# BL808 register map
Vendor: Bouffalo Lab; File version: 0.1
Registers are 32-bit, read-write, reset 0x0 unless marked. A register's access mark holds for its fields unless they carry their own. Offsets are from the block's base; [hi:lo] are bit positions; {n}, {i} and the like mark numbered series; 'fields as' and 'values as' point back to an identical list.

## GLB — Global configuration register
Base 0x20000000
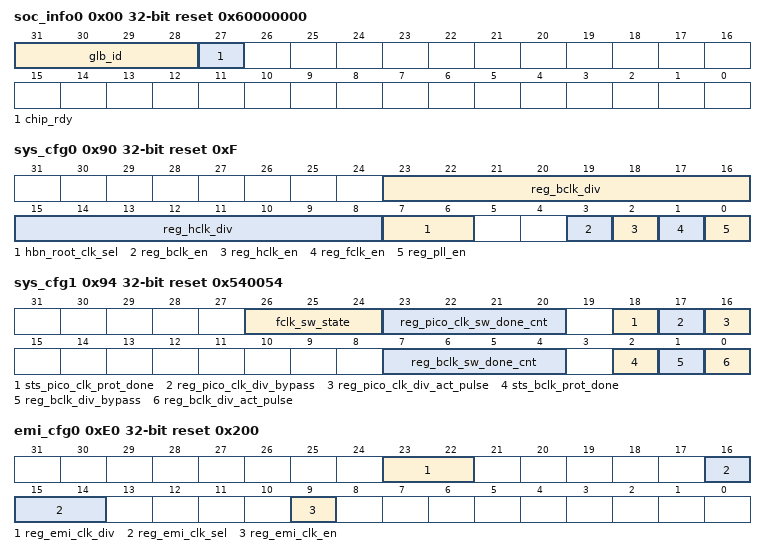
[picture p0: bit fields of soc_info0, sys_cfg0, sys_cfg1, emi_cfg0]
0x00 soc_info0 reset 0x60000000
  [31:28] glb_id ro, [27] chip_rdy ro
0x50 core_cfg16
  [31:0] np_int_sta0 ro
0x54 core_cfg17
  [31:0] np_int_sta1 ro
0x58 core_cfg18
  [31:0] np_int_mask0
0x5C core_cfg19
  [31:0] np_int_mask1
0x60 core_cfg20
  [31:0] np_int_clr0 wo
0x64 core_cfg21
  [31:0] np_int_clr1 wo
0x68 core_cfg22 reset 0xFFFFFFFF
  [31:0] reg_e902_int_en0
0x6C core_cfg23 reset 0xFFFFFFFF
  [31:0] reg_e902_int_en1
0x70 core_cfg24
  [31:0] sts_e902_int_bus_0 ro
0x74 core_cfg25
  [31:0] sts_e902_int_bus_1 ro
0x90 sys_cfg0 reset 0xF
  [23:16] reg_bclk_div, [15:8] reg_hclk_div, [7:6] hbn_root_clk_sel ro, [3] reg_bclk_en, [2] reg_hclk_en, [1] reg_fclk_en, [0] reg_pll_en
0x94 sys_cfg1 reset 0x540054
  [26:24] fclk_sw_state ro, [23:20] reg_pico_clk_sw_done_cnt, [18] sts_pico_clk_prot_done ro, [17] reg_pico_clk_div_bypass, [16] reg_pico_clk_div_act_pulse wo, [7:4] reg_bclk_sw_done_cnt, [2] sts_bclk_prot_done ro, [1] reg_bclk_div_bypass, [0] reg_bclk_div_act_pulse wo
0xA0 bus_cfg0 reset 0xFFFF
  [15:0] rg_apb2_pck_force
0xE0 emi_cfg0 reset 0x200
  [23:22] reg_emi_clk_div, [16:14] reg_emi_clk_sel, [9] reg_emi_clk_en
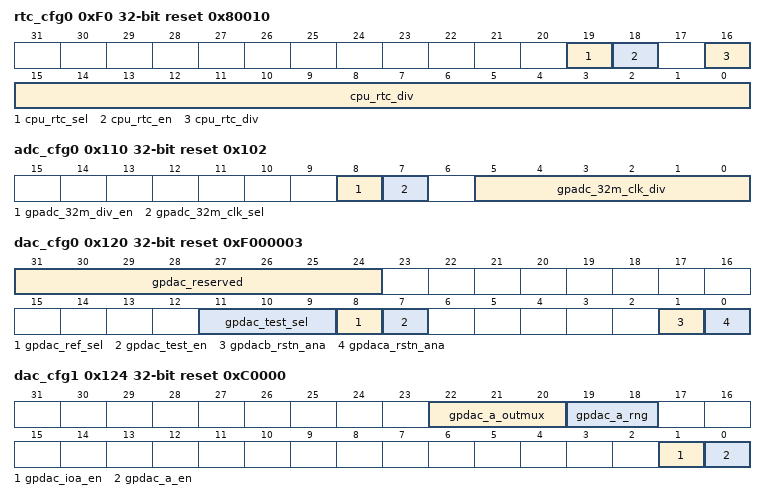
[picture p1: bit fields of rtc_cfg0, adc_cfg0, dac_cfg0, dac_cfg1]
0xF0 rtc_cfg0 reset 0x80010
  [19] cpu_rtc_sel, [18] cpu_rtc_en, [16:0] cpu_rtc_div
0x110 adc_cfg0 reset 0x102
  [8] gpadc_32m_div_en, [7] gpadc_32m_clk_sel, [5:0] gpadc_32m_clk_div
0x120 dac_cfg0 reset 0xF000003
  [31:24] gpdac_reserved, [11:9] gpdac_test_sel, [8] gpdac_ref_sel, [7] gpdac_test_en, [1] gpdacb_rstn_ana, [0] gpdaca_rstn_ana
0x124 dac_cfg1 reset 0xC0000
  [22:20] gpdac_a_outmux, [19:18] gpdac_a_rng, [1] gpdac_ioa_en, [0] gpdac_a_en
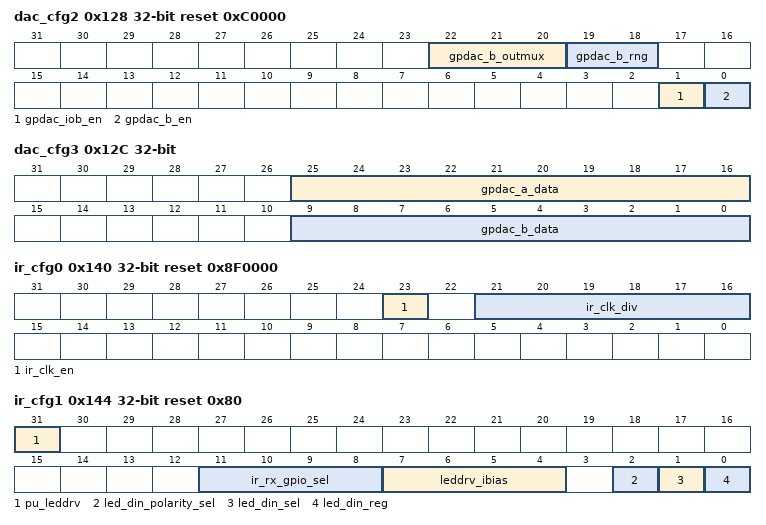
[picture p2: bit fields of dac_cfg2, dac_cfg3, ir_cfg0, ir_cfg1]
0x128 dac_cfg2 reset 0xC0000
  [22:20] gpdac_b_outmux, [19:18] gpdac_b_rng, [1] gpdac_iob_en, [0] gpdac_b_en
0x12C dac_cfg3
  [25:16] gpdac_a_data, [9:0] gpdac_b_data
0x130 dma_cfg0 reset 0xFF000000
  [31:24] dma_clk_en
0x134 dma_cfg1 reset 0xFF000000
  [31:24] dma2_clk_en
0x138 dma_cfg2
  [31:0] reg_dma_cn_sel
0x140 ir_cfg0 reset 0x8F0000
  [23] ir_clk_en, [21:16] ir_clk_div
0x144 ir_cfg1 reset 0x80
  [31] pu_leddrv, [11:8] ir_rx_gpio_sel, [7:4] leddrv_ibias, [2] led_din_polarity_sel, [1] led_din_sel, [0] led_din_reg
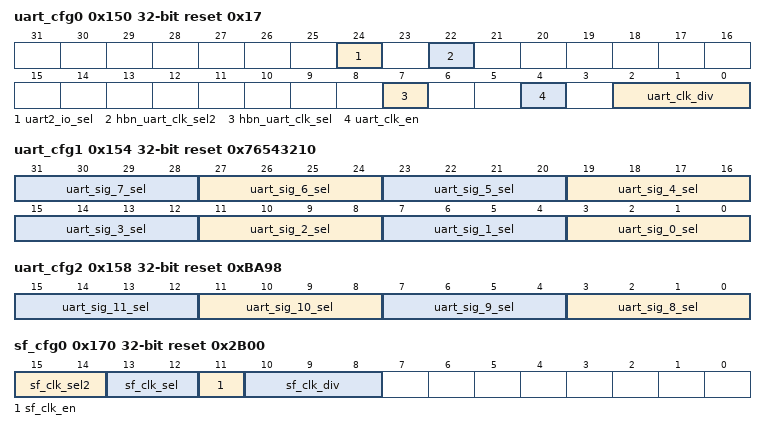
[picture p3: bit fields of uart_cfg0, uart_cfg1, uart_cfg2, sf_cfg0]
0x150 uart_cfg0 reset 0x17
  [24] uart2_io_sel, [22] hbn_uart_clk_sel2 ro, [7] hbn_uart_clk_sel ro, [4] uart_clk_en, [2:0] uart_clk_div
0x154 uart_cfg1 reset 0x76543210
  [4n+3:4n] uart_sig_{n}_sel (n=0..7)
0x158 uart_cfg2 reset 0xBA98
  [4n-29:4n-32] uart_sig_{n}_sel (n=8..11)
0x170 sf_cfg0 reset 0x2B00
  [15:14] sf_clk_sel2, [13:12] sf_clk_sel, [11] sf_clk_en, [10:8] sf_clk_div
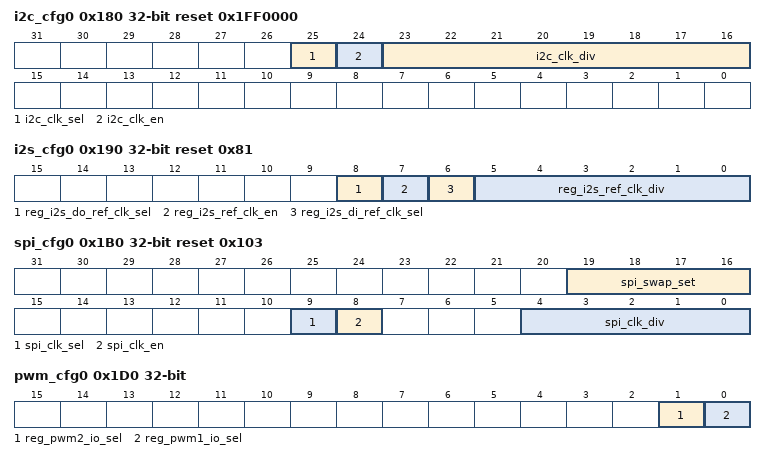
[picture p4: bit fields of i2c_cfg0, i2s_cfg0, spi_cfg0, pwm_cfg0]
0x180 i2c_cfg0 reset 0x1FF0000
  [25] i2c_clk_sel, [24] i2c_clk_en, [23:16] i2c_clk_div
0x190 i2s_cfg0 reset 0x81
  [8] reg_i2s_do_ref_clk_sel, [7] reg_i2s_ref_clk_en, [6] reg_i2s_di_ref_clk_sel, [5:0] reg_i2s_ref_clk_div
0x1B0 spi_cfg0 reset 0x103
  [19:16] spi_swap_set, [9] spi_clk_sel, [8] spi_clk_en, [4:0] spi_clk_div
0x1C0 qdec_cfg0
0x1D0 pwm_cfg0
  [1] reg_pwm2_io_sel, [0] reg_pwm1_io_sel
0x1E0 pdm_cfg0
  [0] reg_pdm_io_sel
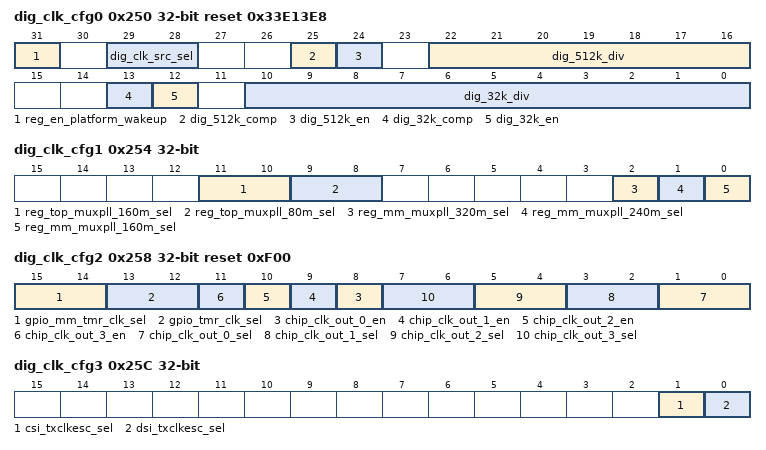
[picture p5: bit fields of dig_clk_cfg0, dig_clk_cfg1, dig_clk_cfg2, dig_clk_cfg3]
0x250 dig_clk_cfg0 reset 0x33E13E8
  [31] reg_en_platform_wakeup, [29:28] dig_clk_src_sel, [25] dig_512k_comp, [24] dig_512k_en, [22:16] dig_512k_div, [13] dig_32k_comp, [12] dig_32k_en, [10:0] dig_32k_div
0x254 dig_clk_cfg1
  [11:10] reg_top_muxpll_160m_sel, [9:8] reg_top_muxpll_80m_sel, [2] reg_mm_muxpll_320m_sel, [1] reg_mm_muxpll_240m_sel, [0] reg_mm_muxpll_160m_sel
0x258 dig_clk_cfg2 reset 0xF00
  [15:14] gpio_mm_tmr_clk_sel, [13:12] gpio_tmr_clk_sel, [n+8] chip_clk_out_{n}_en (n=0..3), [2n+1:2n] chip_clk_out_{n}_sel (n=0..3)
0x25C dig_clk_cfg3
  [1] csi_txclkesc_sel, [0] dsi_txclkesc_sel
0x260 rf_cfg0 reset 0x200
  [9] cfg_inv_rf2_test_clk_o
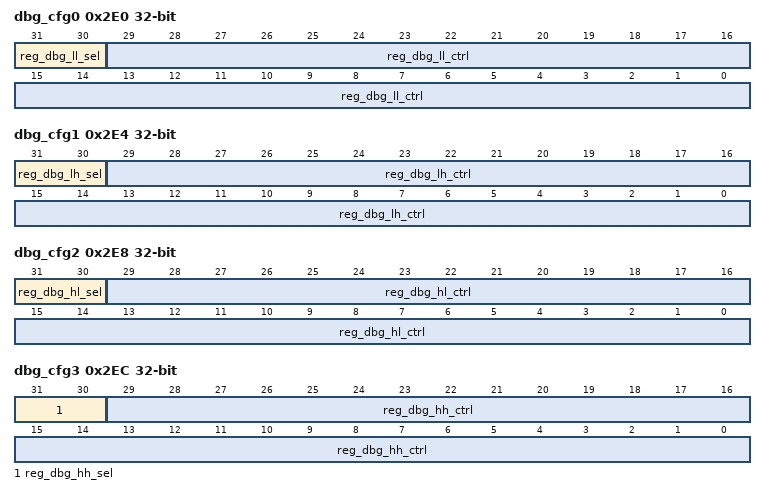
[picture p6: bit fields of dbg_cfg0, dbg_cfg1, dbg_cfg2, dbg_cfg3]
0x2E0 dbg_cfg0
  [31:30] reg_dbg_ll_sel, [29:0] reg_dbg_ll_ctrl
0x2E4 dbg_cfg1
  [31:30] reg_dbg_lh_sel, [29:0] reg_dbg_lh_ctrl
0x2E8 dbg_cfg2
  [31:30] reg_dbg_hl_sel, [29:0] reg_dbg_hl_ctrl
0x2EC dbg_cfg3
  [31:30] reg_dbg_hh_sel, [29:0] reg_dbg_hh_ctrl
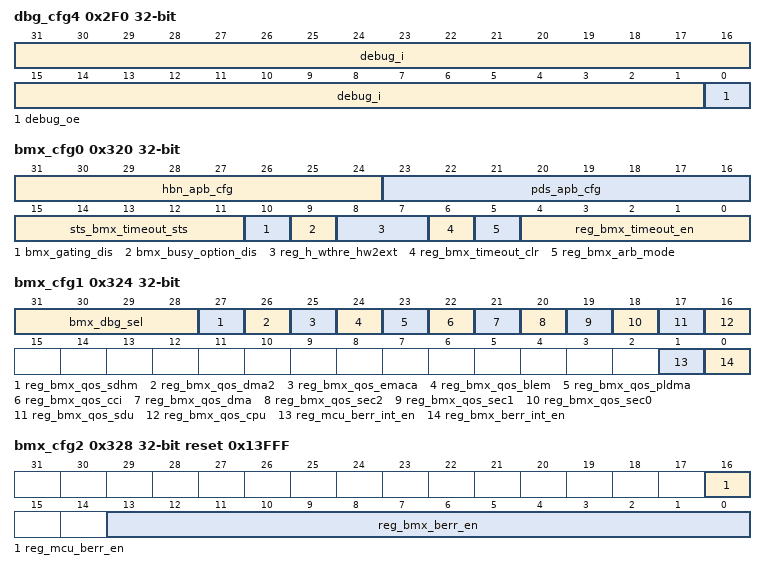
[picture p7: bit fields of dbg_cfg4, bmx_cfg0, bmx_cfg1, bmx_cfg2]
0x2F0 dbg_cfg4
  [31:1] debug_i ro, [0] debug_oe
0x300 mbist_cfg0
  [0] mbist_mode
0x320 bmx_cfg0
  [31:24] hbn_apb_cfg, [23:16] pds_apb_cfg, [15:11] sts_bmx_timeout_sts ro, [10] bmx_gating_dis, [9] bmx_busy_option_dis, [8:7] reg_h_wthre_hw2ext, [6] reg_bmx_timeout_clr, [5] reg_bmx_arb_mode, [4:0] reg_bmx_timeout_en
0x324 bmx_cfg1
  [31:28] bmx_dbg_sel, [27] reg_bmx_qos_sdhm, [26] reg_bmx_qos_dma2, [25] reg_bmx_qos_emaca, [24] reg_bmx_qos_blem, [23] reg_bmx_qos_pldma, [22] reg_bmx_qos_cci, [21] reg_bmx_qos_dma, [20] reg_bmx_qos_sec2, [19] reg_bmx_qos_sec1, [18] reg_bmx_qos_sec0, [17] reg_bmx_qos_sdu, [16] reg_bmx_qos_cpu, [1] reg_mcu_berr_int_en, [0] reg_bmx_berr_int_en
0x328 bmx_cfg2 reset 0x13FFF
  [16] reg_mcu_berr_en, [13:0] reg_bmx_berr_en
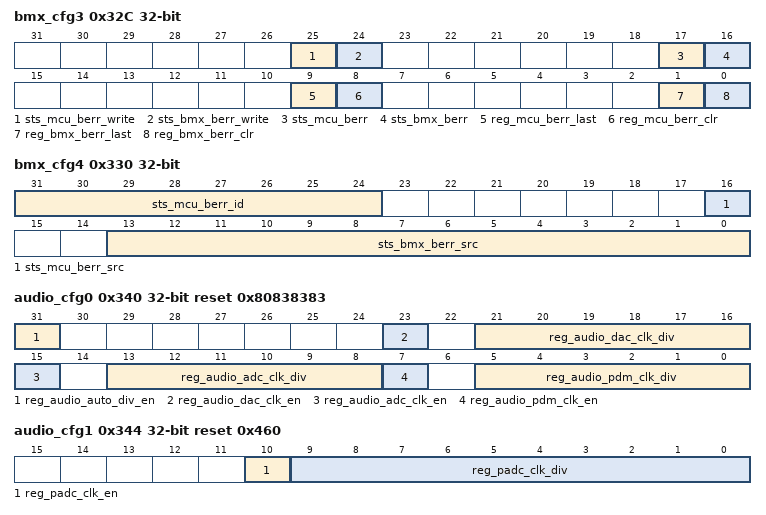
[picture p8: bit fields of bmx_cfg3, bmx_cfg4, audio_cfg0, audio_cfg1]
0x32C bmx_cfg3
  [25] sts_mcu_berr_write ro, [24] sts_bmx_berr_write ro, [17] sts_mcu_berr ro, [16] sts_bmx_berr ro, [9] reg_mcu_berr_last, [8] reg_mcu_berr_clr, [1] reg_bmx_berr_last, [0] reg_bmx_berr_clr
0x330 bmx_cfg4
  [31:24] sts_mcu_berr_id ro, [16] sts_mcu_berr_src ro, [13:0] sts_bmx_berr_src ro
0x334 bmx_cfg5
  [31:0] sts_bmx_berr_addr ro
0x338 bmx_cfg6
  [31:0] sts_mcu_berr_addr ro
0x340 audio_cfg0 reset 0x80838383
  [31] reg_audio_auto_div_en, [23] reg_audio_dac_clk_en, [21:16] reg_audio_dac_clk_div, [15] reg_audio_adc_clk_en, [13:8] reg_audio_adc_clk_div, [7] reg_audio_pdm_clk_en, [5:0] reg_audio_pdm_clk_div
0x344 audio_cfg1 reset 0x460
  [10] reg_padc_clk_en, [9:0] reg_padc_clk_div
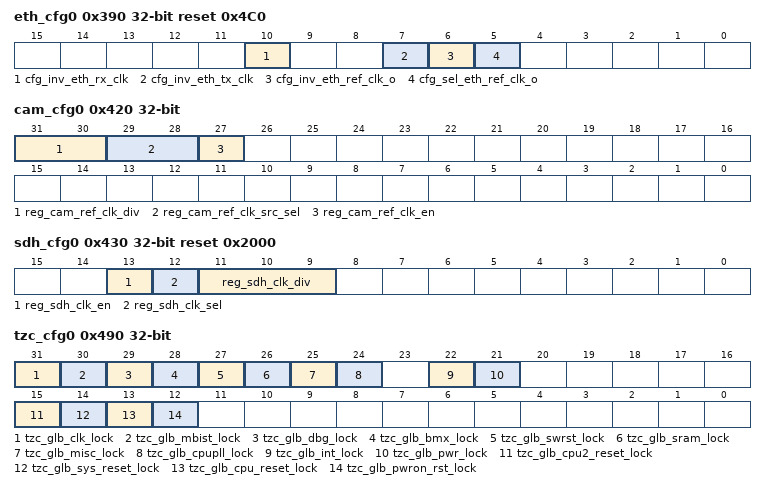
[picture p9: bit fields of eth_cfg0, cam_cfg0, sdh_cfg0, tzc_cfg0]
0x390 eth_cfg0 reset 0x4C0
  [10] cfg_inv_eth_rx_clk, [7] cfg_inv_eth_tx_clk, [6] cfg_inv_eth_ref_clk_o, [5] cfg_sel_eth_ref_clk_o
0x420 cam_cfg0
  [31:30] reg_cam_ref_clk_div, [29:28] reg_cam_ref_clk_src_sel, [27] reg_cam_ref_clk_en
0x430 sdh_cfg0 reset 0x2000
  [13] reg_sdh_clk_en, [12] reg_sdh_clk_sel, [11:9] reg_sdh_clk_div
0x490 tzc_cfg0
  [31] tzc_glb_clk_lock ro, [30] tzc_glb_mbist_lock ro, [29] tzc_glb_dbg_lock ro, [28] tzc_glb_bmx_lock ro, [27] tzc_glb_swrst_lock ro, [26] tzc_glb_sram_lock ro, [25] tzc_glb_misc_lock ro, [24] tzc_glb_cpupll_lock ro, [22] tzc_glb_int_lock ro, [21] tzc_glb_pwr_lock ro, [15] tzc_glb_cpu2_reset_lock ro, [14] tzc_glb_sys_reset_lock ro, [13] tzc_glb_cpu_reset_lock ro, [12] tzc_glb_pwron_rst_lock ro
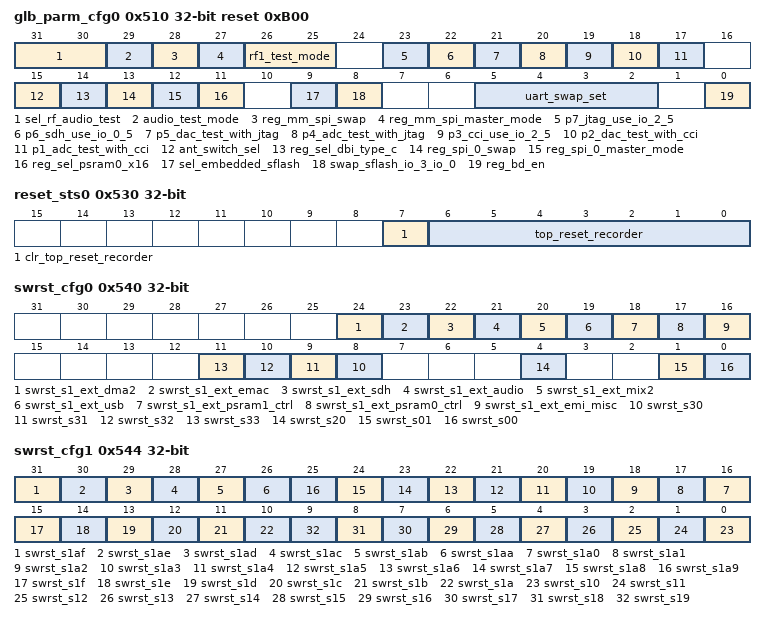
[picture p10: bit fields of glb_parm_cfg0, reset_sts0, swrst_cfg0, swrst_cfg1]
0x510 glb_parm_cfg0 reset 0xB00
  [31:30] sel_rf_audio_test, [29] audio_test_mode, [28] reg_mm_spi_swap, [27] reg_mm_spi_master_mode, [26:25] rf1_test_mode, [23] p7_jtag_use_io_2_5, [22] p6_sdh_use_io_0_5, [21] p5_dac_test_with_jtag, [20] p4_adc_test_with_jtag, [19] p3_cci_use_io_2_5, [18] p2_dac_test_with_cci, [17] p1_adc_test_with_cci, [15] ant_switch_sel, [14] reg_sel_dbi_type_c, [13] reg_spi_0_swap, [12] reg_spi_0_master_mode, [11] reg_sel_psram0_x16, [9] sel_embedded_sflash, [8] swap_sflash_io_3_io_0, [5:2] uart_swap_set, [0] reg_bd_en
0x520 debug_cfg0
0x524 debug_cfg1
  [20] debug_ndreset_gate
0x530 reset_sts0
  [7] clr_top_reset_recorder, [6:0] top_reset_recorder ro
0x540 swrst_cfg0 — swrst_s1_ext + swrst_s3 + swrst_s2
  [24] swrst_s1_ext_dma2, [23] swrst_s1_ext_emac, [22] swrst_s1_ext_sdh, [21] swrst_s1_ext_audio, [20] swrst_s1_ext_mix2, [19] swrst_s1_ext_usb, [18] swrst_s1_ext_psram1_ctrl, [17] swrst_s1_ext_psram0_ctrl, [16] swrst_s1_ext_emi_misc, [n-22] swrst_s{n} (n=30..33), [4] swrst_s20, [1] swrst_s01, [0] swrst_s00
0x544 swrst_cfg1 — swrst_s1
  [31] swrst_s1af, [30] swrst_s1ae, [29] swrst_s1ad, [28] swrst_s1ac, [27] swrst_s1ab, [26] swrst_s1aa, [n+16] swrst_s1a{n} (n=0..9), [15] swrst_s1f, [14] swrst_s1e, [13] swrst_s1d, [12] swrst_s1c, [11] swrst_s1b, [10] swrst_s1a, [n-10] swrst_s{n} (n=10..19)
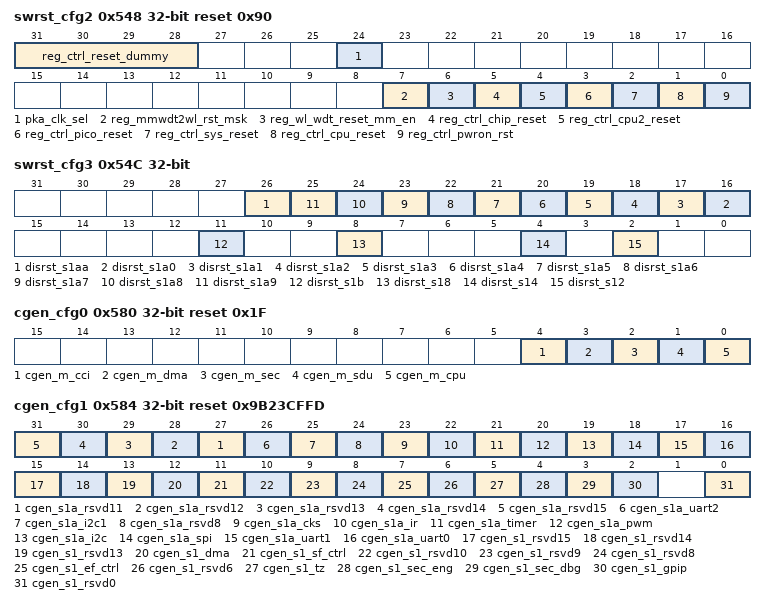
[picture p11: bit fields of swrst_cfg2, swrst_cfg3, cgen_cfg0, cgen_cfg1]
0x548 swrst_cfg2 reset 0x90
  [31:28] reg_ctrl_reset_dummy, [24] pka_clk_sel, [7] reg_mmwdt2wl_rst_msk, [6] reg_wl_wdt_reset_mm_en, [5] reg_ctrl_chip_reset, [4] reg_ctrl_cpu2_reset, [3] reg_ctrl_pico_reset, [2] reg_ctrl_sys_reset, [1] reg_ctrl_cpu_reset, [0] reg_ctrl_pwron_rst
0x54C swrst_cfg3 — Disable hreset
  [26] disrst_s1aa, [n+16] disrst_s1a{n} (n=0..9), [11] disrst_s1b, [8] disrst_s18, [4] disrst_s14, [2] disrst_s12
0x580 cgen_cfg0 reset 0x1F — cgen_m
  [4] cgen_m_cci, [3] cgen_m_dma, [2] cgen_m_sec, [1] cgen_m_sdu, [0] cgen_m_cpu
0x584 cgen_cfg1 reset 0x9B23CFFD — cgen_s1a + cgen_s1
  [n+16] cgen_s1a_rsvd{n} (n=11..15), [26] cgen_s1a_uart2, [25] cgen_s1a_i2c1, [24] cgen_s1a_rsvd8, [23] cgen_s1a_cks, [22] cgen_s1a_ir, [21] cgen_s1a_timer, [20] cgen_s1a_pwm, [19] cgen_s1a_i2c, [18] cgen_s1a_spi, [17] cgen_s1a_uart1, [16] cgen_s1a_uart0, [15] cgen_s1_rsvd15, [14] cgen_s1_rsvd14, [13] cgen_s1_rsvd13, [12] cgen_s1_dma, [11] cgen_s1_sf_ctrl, [10] cgen_s1_rsvd10, [9] cgen_s1_rsvd9, [8] cgen_s1_rsvd8, [7] cgen_s1_ef_ctrl, [6] cgen_s1_rsvd6, [5] cgen_s1_tz, [4] cgen_s1_sec_eng, [3] cgen_s1_sec_dbg, [2] cgen_s1_gpip, [0] cgen_s1_rsvd0
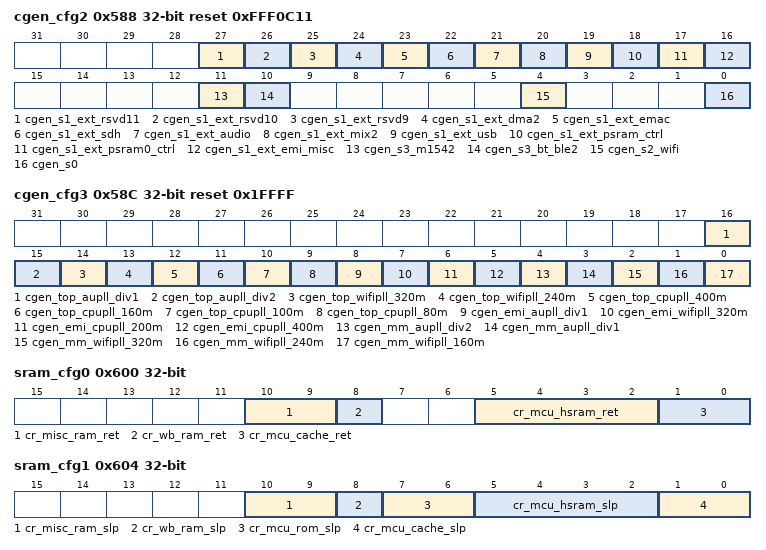
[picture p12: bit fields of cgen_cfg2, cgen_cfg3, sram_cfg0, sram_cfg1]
0x588 cgen_cfg2 reset 0xFFF0C11 — cgen_s1_ext + cgen_s3
  [27] cgen_s1_ext_rsvd11, [26] cgen_s1_ext_rsvd10, [25] cgen_s1_ext_rsvd9, [24] cgen_s1_ext_dma2, [23] cgen_s1_ext_emac, [22] cgen_s1_ext_sdh, [21] cgen_s1_ext_audio, [20] cgen_s1_ext_mix2, [19] cgen_s1_ext_usb, [18] cgen_s1_ext_psram_ctrl, [17] cgen_s1_ext_psram0_ctrl, [16] cgen_s1_ext_emi_misc, [11] cgen_s3_m1542, [10] cgen_s3_bt_ble2, [4] cgen_s2_wifi, [0] cgen_s0
0x58C cgen_cfg3 reset 0x1FFFF
  [16] cgen_top_aupll_div1, [15] cgen_top_aupll_div2, [14] cgen_top_wifipll_320m, [13] cgen_top_wifipll_240m, [12] cgen_top_cpupll_400m, [11] cgen_top_cpupll_160m, [10] cgen_top_cpupll_100m, [9] cgen_top_cpupll_80m, [8] cgen_emi_aupll_div1, [7] cgen_emi_wifipll_320m, [6] cgen_emi_cpupll_200m, [5] cgen_emi_cpupll_400m, [4] cgen_mm_aupll_div2, [3] cgen_mm_aupll_div1, [2] cgen_mm_wifipll_320m, [1] cgen_mm_wifipll_240m, [0] cgen_mm_wifipll_160m
{0x5C0+4i} hw_rsv{i} (i=0..2)
0x5CC hw_rsv3 reset 0xFFFFFFFF
0x600 sram_cfg0 — reg_sram_ret
  [10:9] cr_misc_ram_ret, [8] cr_wb_ram_ret, [5:2] cr_mcu_hsram_ret, [1:0] cr_mcu_cache_ret
0x604 sram_cfg1 — reg_sram_slp
  [10:9] cr_misc_ram_slp, [8] cr_wb_ram_slp, [7:6] cr_mcu_rom_slp, [5:2] cr_mcu_hsram_slp, [1:0] cr_mcu_cache_slp
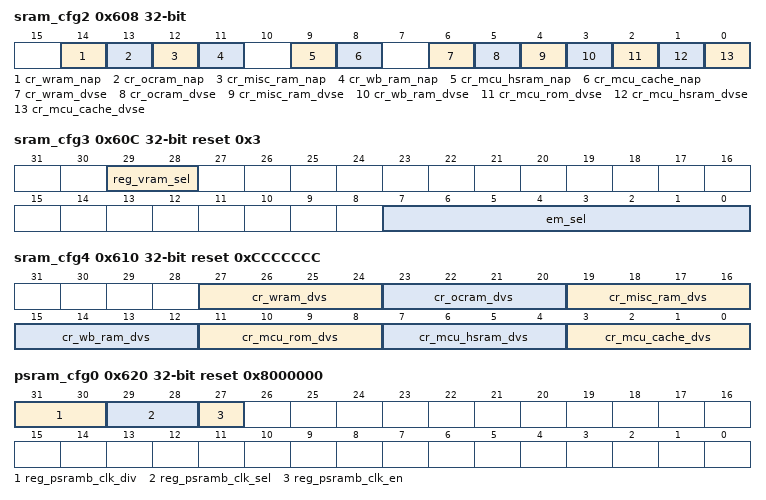
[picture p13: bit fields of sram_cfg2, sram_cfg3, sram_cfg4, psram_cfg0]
0x608 sram_cfg2 — reg_sram_parm
  [14] cr_wram_nap, [13] cr_ocram_nap, [12] cr_misc_ram_nap, [11] cr_wb_ram_nap, [9] cr_mcu_hsram_nap, [8] cr_mcu_cache_nap, [6] cr_wram_dvse, [5] cr_ocram_dvse, [4] cr_misc_ram_dvse, [3] cr_wb_ram_dvse, [2] cr_mcu_rom_dvse, [1] cr_mcu_hsram_dvse, [0] cr_mcu_cache_dvse
0x60C sram_cfg3 reset 0x3
  [29:28] reg_vram_sel, [7:0] em_sel
0x610 sram_cfg4 reset 0xCCCCCCC — reg_sram_parm2
  [27:24] cr_wram_dvs, [23:20] cr_ocram_dvs, [19:16] cr_misc_ram_dvs, [15:12] cr_wb_ram_dvs, [11:8] cr_mcu_rom_dvs, [7:4] cr_mcu_hsram_dvs, [3:0] cr_mcu_cache_dvs
0x620 psram_cfg0 reset 0x8000000
  [31:30] reg_psramb_clk_div, [29:28] reg_psramb_clk_sel, [27] reg_psramb_clk_en
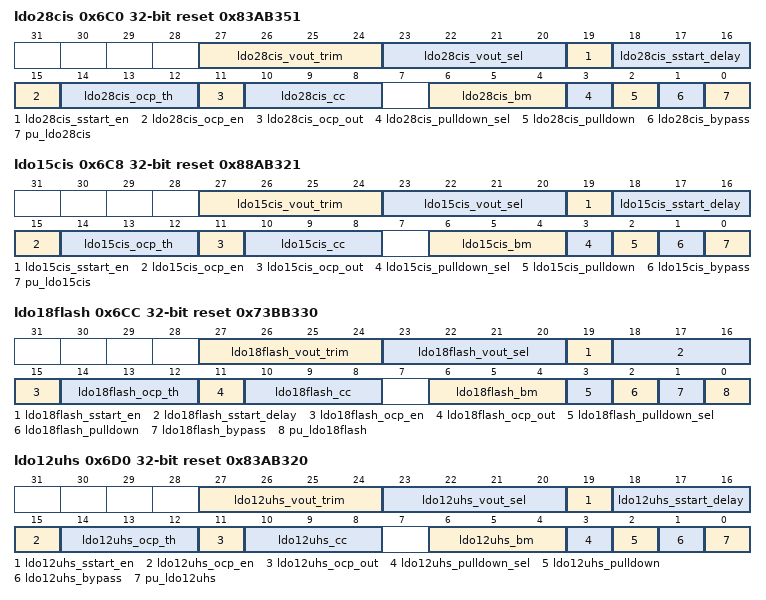
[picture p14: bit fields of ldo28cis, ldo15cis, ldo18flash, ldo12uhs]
0x6C0 ldo28cis reset 0x83AB351
  [27:24] ldo28cis_vout_trim, [23:20] ldo28cis_vout_sel, [19] ldo28cis_sstart_en, [18:16] ldo28cis_sstart_delay, [15] ldo28cis_ocp_en, [14:12] ldo28cis_ocp_th, [11] ldo28cis_ocp_out ro, [10:8] ldo28cis_cc, [6:4] ldo28cis_bm, [3] ldo28cis_pulldown_sel, [2] ldo28cis_pulldown, [1] ldo28cis_bypass, [0] pu_ldo28cis
0x6C4 ldo18io
0x6C8 ldo15cis reset 0x88AB321
  [27:24] ldo15cis_vout_trim, [23:20] ldo15cis_vout_sel, [19] ldo15cis_sstart_en, [18:16] ldo15cis_sstart_delay, [15] ldo15cis_ocp_en, [14:12] ldo15cis_ocp_th, [11] ldo15cis_ocp_out ro, [10:8] ldo15cis_cc, [6:4] ldo15cis_bm, [3] ldo15cis_pulldown_sel, [2] ldo15cis_pulldown, [1] ldo15cis_bypass, [0] pu_ldo15cis
0x6CC ldo18flash reset 0x73BB330
  [27:24] ldo18flash_vout_trim, [23:20] ldo18flash_vout_sel, [19] ldo18flash_sstart_en, [18:16] ldo18flash_sstart_delay, [15] ldo18flash_ocp_en, [14:12] ldo18flash_ocp_th, [11] ldo18flash_ocp_out ro, [10:8] ldo18flash_cc, [6:4] ldo18flash_bm, [3] ldo18flash_pulldown_sel, [2] ldo18flash_pulldown, [1] ldo18flash_bypass, [0] pu_ldo18flash
0x6D0 ldo12uhs reset 0x83AB320
  [27:24] ldo12uhs_vout_trim, [23:20] ldo12uhs_vout_sel, [19] ldo12uhs_sstart_en, [18:16] ldo12uhs_sstart_delay, [15] ldo12uhs_ocp_en, [14:12] ldo12uhs_ocp_th, [11] ldo12uhs_ocp_out ro, [10:8] ldo12uhs_cc, [6:4] ldo12uhs_bm, [3] ldo12uhs_pulldown_sel, [2] ldo12uhs_pulldown, [1] ldo12uhs_bypass, [0] pu_ldo12uhs
0x6F0 proc_mon reset 0x400
  [28] ring_freq_rdy ro, [27:12] ring_freq ro, [11:8] refcount_div_onehot, [5] rstn_refcount, [4] rstn_ringcount, [3] osc_sel, [2] osc_en_lvt, [1] osc_en_rvt, [0] pu_proc_mon
0x700 dll_cfg0
0x790 mipi_pll_cfg0 reset 0x125
  [10] pu_mipipll, [9] pu_mipipll_sfreg, [8] pu_mipipll_cp, [5] pu_mipipll_fbdv, [2] mipipll_fbdv_rstb, [0] mipipll_sdm_rstb
0x794 mipi_pll_cfg1 reset 0x1100232
  [25:24] mipipll_vg13_sel, [21:20] mipipll_vg11_sel, [17:16] mipipll_refclk_sel, [11:8] mipipll_refdiv_ratio, [7] mipipll_even_div_en, [6:0] mipipll_even_div_ratio
0x798 mipi_pll_cfg2 reset 0x1E31
  [12] mipipll_pfd_en, [11] mipipll_cp_ota_en, [10] mipipll_cp_opamp_en, [9] mipipll_cp_startup_en, [8] mipipll_int_frac_sw, [7:6] mipipll_icp_1u, [5:4] mipipll_icp_5u, [0] mipipll_sel_cp_bias
0x79C mipi_pll_cfg3 reset 0x11A011
  [20] mipipll_fast_lock_en, [19] mipipll_lf_test_en, [18:16] mipipll_rz, [15:14] mipipll_cz, [13:12] mipipll_c3, [8] mipipll_r4_short, [5:4] mipipll_r4, [0] mipipll_c4_en
0x7A0 mipi_pll_cfg4 reset 0x8311
  [16:15] mipipll_lock_win_sel, [12] mipipll_lock_clk_inv_en, [10:9] mipipll_lock_clk_sel, [8] mipipll_lock_det_en, [5:4] mipipll_sel_fb_clk, [1:0] mipipll_sel_sample_clk
0x7A4 mipi_pll_cfg5 reset 0x415
  [10] mipipll_vco_postdiv_clk_en, [9:7] mipipll_vco_postdiv_sel, [5] mipipll_vco_vdd_ctrl_extra, [4:3] mipipll_vco_vdd_ctrl, [2:0] mipipll_vco_speed
0x7A8 mipi_pll_cfg6 reset 0x25800
  [24] mipipll_sdm_bypass, [18:0] mipipll_sdmin
0x7AC mipi_pll_cfg7 reset 0x1
  [2:1] mipipll_sdm_dith_sel, [0] mipipll_sdm_order_sel
0x7B0 mipi_pll_cfg8 reset 0x400
  [10] mipipll_dtest_pull_down, [8] mipipll_dten_pll_locked, [7] mipipll_dten_pupll, [6] mipipll_dten_fsdm, [5] mipipll_dten_fref, [4] mipipll_dten_ckin, [2] mipipll_ten_sfreg, [1] mipipll_ten, [0] mipipll_dc_tp_out_en
0x7B4 mipi_pll_cfg9 reset 0x15640
  [16] mipipll_ssc_start_gate_en, [14:12] mipipll_ssc_gain, [11:4] mipipll_ssc_cnt, [0] mipipll_ssc_en
0x7D0 uhs_pll_cfg0 reset 0x125
  [10] pu_uhspll, [9] pu_uhspll_sfreg, [8] pu_uhspll_cp, [5] pu_uhspll_fbdv, [2] uhspll_fbdv_rstb, [0] uhspll_sdm_rstb
0x7D4 uhs_pll_cfg1 reset 0x1100254
  [25:24] uhspll_vg13_sel, [21:20] uhspll_vg11_sel, [17:16] uhspll_refclk_sel, [11:8] uhspll_refdiv_ratio, [7] uhspll_even_div_en, [6:0] uhspll_even_div_ratio
0x7D8 uhs_pll_cfg2 reset 0x1E31
  [12] uhspll_pfd_en, [11] uhspll_cp_ota_en, [10] uhspll_cp_opamp_en, [9] uhspll_cp_startup_en, [8] uhspll_int_frac_sw, [7:6] uhspll_icp_1u, [5:4] uhspll_icp_5u, [0] uhspll_sel_cp_bias
0x7DC uhs_pll_cfg3 reset 0x11A011
  [20] uhspll_fast_lock_en, [19] uhspll_lf_test_en, [18:16] uhspll_rz, [15:14] uhspll_cz, [13:12] uhspll_c3, [8] uhspll_r4_short, [5:4] uhspll_r4, [0] uhspll_c4_en
0x7E0 uhs_pll_cfg4 reset 0x8311
  [16:15] uhspll_lock_win_sel, [12] uhspll_lock_clk_inv_en, [10:9] uhspll_lock_clk_sel, [8] uhspll_lock_det_en, [5:4] uhspll_sel_fb_clk, [1:0] uhspll_sel_sample_clk
0x7E4 uhs_pll_cfg5 reset 0x41F
  [10] uhspll_vco_postdiv_clk_en, [9:7] uhspll_vco_postdiv_sel, [5] uhspll_vco_vdd_ctrl_extra, [4:3] uhspll_vco_vdd_ctrl, [2:0] uhspll_vco_speed
0x7E8 uhs_pll_cfg6 reset 0x34800
  [24] uhspll_sdm_bypass, [18:0] uhspll_sdmin
0x7EC uhs_pll_cfg7 reset 0x1
  [2:1] uhspll_sdm_dith_sel, [0] uhspll_sdm_order_sel
0x7F0 uhs_pll_cfg8 reset 0x400
  [10] uhspll_dtest_pull_down, [8] uhspll_dten_pll_locked, [7] uhspll_dten_pupll, [6] uhspll_dten_fsdm, [5] uhspll_dten_fref, [4] uhspll_dten_ckin, [2] uhspll_ten_sfreg, [1] uhspll_ten, [0] uhspll_dc_tp_out_en
0x7F4 uhs_pll_cfg9 reset 0x15640
  [16] uhspll_ssc_start_gate_en, [14:12] uhspll_ssc_gain, [11:4] uhspll_ssc_cnt, [0] uhspll_ssc_en
0x810 wifi_pll_cfg0 reset 0x9EF
  [11] pu_wifipll_clktree, [10] pu_wifipll, [9] pu_wifipll_sfreg, [8] pu_wifipll_cp, [7] pu_wifipll_pfd, [6] pu_wifipll_clamp_op, [5] pu_wifipll_fbdv, [4] pu_wifipll_postdiv, [3] wifipll_refdiv_rstb, [2] wifipll_fbdv_rstb, [1] wifipll_postdiv_rstb, [0] wifipll_sdm_rstb
0x814 wifi_pll_cfg1 reset 0x1110216
  [25:24] wifipll_vg13_sel, [21:20] wifipll_vg11_sel, [17:16] wifipll_refclk_sel, [11:8] wifipll_refdiv_ratio, [6:0] wifipll_postdiv
0x818 wifi_pll_cfg2 reset 0x621
  [10] wifipll_cp_opamp_en, [9] wifipll_cp_startup_en, [8] wifipll_int_frac_sw, [7:6] wifipll_icp_1u, [5:4] wifipll_icp_5u, [0] wifipll_sel_cp_bias
0x81C wifi_pll_cfg3 reset 0x36120
  [18:16] wifipll_rz, [15:14] wifipll_cz, [13:12] wifipll_c3, [8] wifipll_r4_short, [5:4] wifipll_r4, [0] wifipll_c4_en
0x820 wifi_pll_cfg4 reset 0x111
  [8] wifipll_sdmclk_sel, [5:4] wifipll_sel_fb_clk, [1:0] wifipll_sel_sample_clk
0x824 wifi_pll_cfg5 reset 0x1105
  [12] wifipll_vco_div3_en, [8] wifipll_vco_div2_en, [4] wifipll_vco_div1_en, [2:0] wifipll_vco_speed
0x828 wifi_pll_cfg6 reset 0x1800000
  [31] wifipll_sdm_ctrl_hw, [29] wifipll_sdm_bypass_hw ro, [28] wifipll_sdm_bypass, [25:0] wifipll_sdmin
0x82C wifi_pll_cfg7 reset 0x32
  [17:16] wifipll_sdm_sig_dith_sel, [13:12] wifipll_sdm_sig_prbs_sel, [8] wifipll_sdm_noi_prbs_en, [5:4] wifipll_sdm_noi_prbs_sel, [1:0] wifipll_sdm_order_sel
0x830 wifi_pll_cfg8 reset 0x11FF
  [31] wifipll_en_ctrl_hw, [12] wifipll_en_div2_hw ro, [10] en_wifipll_div30_bz_adc, [9] wifipll_sel_div2_div4, [8] wifipll_en_div30, [7] wifipll_en_div20, [6] wifipll_en_div12, [5] wifipll_en_div10, [4] wifipll_en_div8, [3] wifipll_en_div6, [2] wifipll_en_div5, [1] wifipll_en_div4, [0] wifipll_en_div2
0x834 wifi_pll_cfg9 reset 0x1000
  [12] dtest_wifipll_pulldown, [11] usbpll_dtest_clkout_en, [10] usbpll_dtest_pclk_en, [9] dten_wifipll_postdiv_clk, [8] dten_wifipll_div10, [7] dten_wifipll_div30, [6] dten_wifipll_fsdm, [5] dten_wifipll_fref, [4] dten_wifipll_fin, [2] ten_wifipll_sfreg, [1] ten_wifipll, [0] wifipll_dc_tp_out_en
0x838 wifi_pll_cfg10 reset 0x11300434
  [29] pu_usbpll_mmdiv, [28] usbpll_rstb, [25:24] usbpll_sel_sample_clk, [21] usbpll_clkout_en, [20] usbpll_div2_en, [17:16] usbpll_sdm_sig_dith_sel, [10] usbpll_sdm_order_sel, [9] usbpll_sdm_bypass, [8] usbpll_ssc_en, [6:4] usbpll_ssc_gain, [3] usbpll_ssc_start_gate_en, [2] usbpll_ssc_start
0x83C wifi_pll_cfg11 reset 0x28000
  [18:0] usbpll_sdmin
0x840 wifi_pll_cfg12 reset 0xF0
  [8:0] usbpll_ssc_cnt
0x844 wifi_pll_cfg13
  [31] wifipll_dl_ctrl_2, [30] wifipll_dl_ctrl_4, [29] wifipll_dl_ctrl_5, [28] wifipll_dl_ctrl_6, [27] wifipll_dl_ctrl_8, [26] wifipll_dl_ctrl_10, [25] wifipll_dl_ctrl_12, [24] wifipll_dl_ctrl_20, [23] wifipll_dl_ctrl_30, [22] wifipll_dl_ctrl_30_bz_adc, [21] usbpll_dl_ctrl, [15:0] wifipll_resv
0x8A4 gauge reset 0x80029A8
  [31] gauge_bg_pu, [30] gauge_vcm_pu, [29] gauge_ldo_pu, [28] ntc_bias_en, [27:24] ntc_bias_sel, [23] ten_gauge_power, [22:20] tmux_gauge_power, [18] gauge_lp_mode, [17] gauge_channel_en, [16] gauge_channel_sel, [15] gauge_sdm_pu, [14:13] gauge_quan_gain, [12] gauge_sel_edge, [11] gauge_chop_en, [10:8] gauge_chop_freq, [7] gauge_chop_phas, [6] gauge_ckb_en, [5] gauge_dem_en, [4:3] gauge_ictrl_adc, [2:0] gauge_reserve
0x8B8 gauge_rx_fifo_ctrl reset 0x3010000
  [25:24] gauge_rx_data_mode, [18:16] gauge_rx_trg_level, [15:14] gauge_rx_drq_cnt, [8] gauge_rx_ch_en, [5] gauge_rx_data_res, [4] gauge_rx_drq_en, [3] gauge_rxa_int_en, [2] gauge_rxu_int_en, [1] gauge_rxo_int_en, [0] gauge_rx_fifo_flush wo
0x8BC gauge_rx_fifo_status
  [24] gauge_rxa ro, [18:16] gauge_rxa_cnt ro, [4] gauge_rxa_int ro, [2] gauge_rxu_int ro, [1] gauge_rxo_int ro
0x8C0 gauge_rx_fifo_data
  [31:0] gauge_rx_data ro
{0x8C4+4i} gpio_cfg{i} reset 0x400B02 (i=0..2)
  [31:30] reg_gpio_{i}_mode, [28] reg_gpio_{i}_i ro, [26] reg_gpio_{i}_clr wo, [25] reg_gpio_{i}_set wo, [24] reg_gpio_{i}_o, [22] reg_gpio_{i}_int_mask, [21] gpio_{i}_int_stat ro, [20] reg_gpio_{i}_int_clr, [19:16] reg_gpio_{i}_int_mode_set, [12:8] reg_gpio_{i}_func_sel, [6] reg_gpio_{i}_oe, [5] reg_gpio_{i}_pd, [4] reg_gpio_{i}_pu, [3:2] reg_gpio_{i}_drv, [1] reg_gpio_{i}_smt, [0] reg_gpio_{i}_ie
{0x8C4+4i} gpio_cfg{i} reset 0x400F03 (i=3..5)
  fields as gpio_cfg0
{0x8C4+4i} gpio_cfg{i} reset 0x400B02 (i=6..45)
  fields as gpio_cfg0
{0x8C4+4i} gpio_cfg{i} reset 0x2 (i=46..63)
  [5] reg_gpio_{i}_pd, [4] reg_gpio_{i}_pu, [3:2] reg_gpio_{i}_drv, [1] reg_gpio_{i}_smt, [0] reg_gpio_{i}_ie
0xAC4 gpio_cfg128
  [n] reg2_gpio_{n}_i ro (n=0..31)
0xAC8 gpio_cfg129
  [n-32] reg2_gpio_{n}_i ro (n=32..45)
0xAE4 gpio_cfg136
  [n] reg2_gpio_{n}_o (n=0..31)
0xAE8 gpio_cfg137
  [n-32] reg2_gpio_{n}_o (n=32..45)
0xAEC gpio_cfg138
  [n] reg2_gpio_{n}_set wo (n=0..31)
0xAF0 gpio_cfg139
  [n-32] reg2_gpio_{n}_set wo (n=32..45)
0xAF4 gpio_cfg140
  [n] reg2_gpio_{n}_clr wo (n=0..31)
0xAF8 gpio_cfg141
  [n-32] reg2_gpio_{n}_clr wo (n=32..45)
0xAFC gpio_cfg142 reset 0xC8C8C800
  [31:24] cr_code1_high_time, [23:16] cr_code0_high_time, [15:7] cr_code_total_time, [2] cr_invert_code1_high, [1] cr_invert_code0_high, [0] cr_gpio_tx_en
0xB00 gpio_cfg143 reset 0xE3808000
  [31] cr_gpio_tx_fer_en, [30] cr_gpio_tx_fifo_en, [29] cr_gpio_tx_end_en, [28] r_gpio_tx_fer_int ro, [27] r_gpio_tx_fifo_int ro, [26] r_gpio_tx_end_int ro, [25] cr_gpio_tx_fer_mask, [24] cr_gpio_tx_fifo_mask, [23] cr_gpio_tx_end_mask, [22:16] cr_gpio_tx_fifo_th, [15:8] gpio_tx_fifo_cnt ro, [7] cr_gpio_dma_park_value, [5] gpio_tx_fifo_underflow ro, [4] gpio_tx_fifo_overflow ro, [3] gpio_tx_end_clr wo, [2] gpio_tx_fifo_clr wo, [1] cr_gpio_dma_out_sel_latch, [0] cr_gpio_dma_tx_en
0xB04 gpio_cfg144
